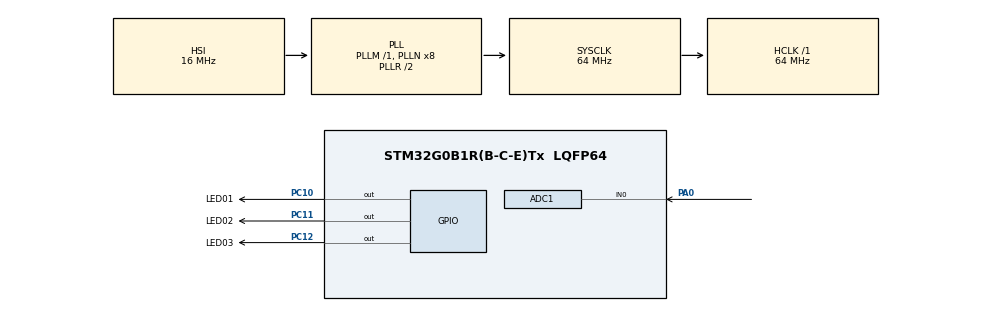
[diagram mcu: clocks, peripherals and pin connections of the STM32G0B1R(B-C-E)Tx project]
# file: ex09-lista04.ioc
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ADC1.Channel-1\#ChannelRegularConversion=ADC_CHANNEL_0
ADC1.NbrOfConversionFlag=1
ADC1.Rank-1\#ChannelRegularConversion=1
ADC1.SamplingTime-1\#ChannelRegularConversion=ADC_SAMPLINGTIME_COMMON_1
ADC1.SamplingTimeCommon1=ADC_SAMPLETIME_19CYCLES_5
ADC1.SelectedChannel=ADC_CHANNEL_0
ADC1.master=1
Mcu.Family=STM32G0
Mcu.Name=STM32G0B1R(B-C-E)Tx
Mcu.Package=LQFP64
PA0.Mode=IN0
PA0.Signal=ADC1_IN0
PA13.Mode=Serial_Wire
PA13.Signal=SYS_SWDIO
PA14-BOOT0.Mode=Serial_Wire
PA14-BOOT0.Signal=SYS_SWCLK
PC10.GPIO_Label=LED01
PC10.Signal=GPIO_Output
PC11.GPIO_Label=LED02
PC11.Signal=GPIO_Output
PC12.GPIO_Label=LED03
PC12.Signal=GPIO_Output
ProjectManager.HeapSize=0x200
ProjectManager.StackSize=0x400
ProjectManager.TargetToolchain=STM32CubeIDE
RCC.ADCFreq_Value=64000000
RCC.AHBFreq_Value=64000000
RCC.CortexFreq_Value=64000000
RCC.EXTERNAL_CLOCK_VALUE=48000
RCC.HCLKFreq_Value=64000000
RCC.HSE_VALUE=8000000
RCC.HSI48_VALUE=48000000
RCC.HSI_VALUE=16000000
RCC.LSE_VALUE=32768
RCC.SYSCLKFreq_VALUE=64000000
RCC.SYSCLKSource=RCC_SYSCLKSOURCE_PLLCLK
RCC.USBFreq_Value=48000000
RCC.VCOOutputFreq_Value=128000000
VP_SYS_VS_DBSignals.Mode=DisableDeadBatterySignals
board=custom

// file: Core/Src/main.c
/* USER CODE BEGIN Header */
/**
  ******************************************************************************
  * @file           : main.c
  * @brief          : Main program body
  ******************************************************************************
  * @attention
  *
  * Copyright (c) 2022 STMicroelectronics.
  * All rights reserved.
  *
  * This software is licensed under terms that can be found in the LICENSE file
  * in the root directory of this software component.
  * If no LICENSE file comes with this software, it is provided AS-IS.
  *
  ******************************************************************************
  */
/* USER CODE END Header */
#include "main.h"

/* USER CODE BEGIN Includes */
#include <stdint.h>
/* USER CODE END Includes */

ADC_HandleTypeDef hadc1;

void SystemClock_Config(void);
static void MX_GPIO_Init(void);
static void MX_ADC1_Init(void);

/* USER CODE BEGIN 0 */
uint16_t pot, r2, r1=270;
float volt;
/* USER CODE END 0 */

int main(void)
{

  /* MCU Configuration--------------------------------------------------------*/

  /* Reset of all peripherals, Initializes the Flash interface and the Systick. */
  HAL_Init();

  /* Configure the system clock */
  SystemClock_Config();

  /* Initialize all configured peripherals */
  MX_GPIO_Init();
  MX_ADC1_Init();
  /* USER CODE BEGIN 2 */
  HAL_ADCEx_Calibration_Start(&hadc1);
  /* USER CODE END 2 */

  /* Infinite loop */
  /* USER CODE BEGIN WHILE */
  while (1)
  {

	  //iniciando conversão
	  HAL_ADC_Start(&hadc1);

	  //tempo de espera para completar ciclo
	  HAL_ADC_PollForConversion(&hadc1, 1);

	  pot = HAL_ADC_GetValue(&hadc1);

	  //tempo de espera para completar ciclo
	  HAL_ADC_PollForConversion(&hadc1, 1);

	  volt = 3.3 / 4095.0 * pot;

	  r2=(volt/(3.3-volt))*r1;

    /* USER CODE END WHILE */

  }
}

void SystemClock_Config(void)
{
  RCC_OscInitTypeDef RCC_OscInitStruct = {0};
  RCC_ClkInitTypeDef RCC_ClkInitStruct = {0};

  /** Configure the main internal regulator output voltage
  */
  HAL_PWREx_ControlVoltageScaling(PWR_REGULATOR_VOLTAGE_SCALE1);
  /** Initializes the RCC Oscillators according to the specified parameters
  * in the RCC_OscInitTypeDef structure.
  */
  RCC_OscInitStruct.OscillatorType = RCC_OSCILLATORTYPE_HSI;
  RCC_OscInitStruct.HSIState = RCC_HSI_ON;
  RCC_OscInitStruct.HSIDiv = RCC_HSI_DIV1;
  RCC_OscInitStruct.HSICalibrationValue = RCC_HSICALIBRATION_DEFAULT;
  RCC_OscInitStruct.PLL.PLLState = RCC_PLL_ON;
  RCC_OscInitStruct.PLL.PLLSource = RCC_PLLSOURCE_HSI;
  RCC_OscInitStruct.PLL.PLLM = RCC_PLLM_DIV1;
  RCC_OscInitStruct.PLL.PLLN = 8;
  RCC_OscInitStruct.PLL.PLLP = RCC_PLLP_DIV2;
  RCC_OscInitStruct.PLL.PLLQ = RCC_PLLQ_DIV2;
  RCC_OscInitStruct.PLL.PLLR = RCC_PLLR_DIV2;
  if (HAL_RCC_OscConfig(&RCC_OscInitStruct) != HAL_OK)
  {
    Error_Handler();
  }
  /** Initializes the CPU, AHB and APB buses clocks
  */
  RCC_ClkInitStruct.ClockType = RCC_CLOCKTYPE_HCLK|RCC_CLOCKTYPE_SYSCLK
                              |RCC_CLOCKTYPE_PCLK1;
  RCC_ClkInitStruct.SYSCLKSource = RCC_SYSCLKSOURCE_PLLCLK;
  RCC_ClkInitStruct.AHBCLKDivider = RCC_SYSCLK_DIV1;
  RCC_ClkInitStruct.APB1CLKDivider = RCC_HCLK_DIV1;

  if (HAL_RCC_ClockConfig(&RCC_ClkInitStruct, FLASH_LATENCY_2) != HAL_OK)
  {
    Error_Handler();
  }
}

static void MX_ADC1_Init(void)
{

  ADC_ChannelConfTypeDef sConfig = {0};

  /** Configure the global features of the ADC (Clock, Resolution, Data Alignment and number of conversion)
  */
  hadc1.Instance = ADC1;
  hadc1.Init.ClockPrescaler = ADC_CLOCK_SYNC_PCLK_DIV2;
  hadc1.Init.Resolution = ADC_RESOLUTION_12B;
  hadc1.Init.DataAlign = ADC_DATAALIGN_RIGHT;
  hadc1.Init.ScanConvMode = ADC_SCAN_DISABLE;
  hadc1.Init.EOCSelection = ADC_EOC_SINGLE_CONV;
  hadc1.Init.LowPowerAutoWait = DISABLE;
  hadc1.Init.LowPowerAutoPowerOff = DISABLE;
  hadc1.Init.ContinuousConvMode = DISABLE;
  hadc1.Init.NbrOfConversion = 1;
  hadc1.Init.DiscontinuousConvMode = DISABLE;
  hadc1.Init.ExternalTrigConv = ADC_SOFTWARE_START;
  hadc1.Init.ExternalTrigConvEdge = ADC_EXTERNALTRIGCONVEDGE_NONE;
  hadc1.Init.DMAContinuousRequests = DISABLE;
  hadc1.Init.Overrun = ADC_OVR_DATA_PRESERVED;
  hadc1.Init.SamplingTimeCommon1 = ADC_SAMPLETIME_19CYCLES_5;
  hadc1.Init.SamplingTimeCommon2 = ADC_SAMPLETIME_1CYCLE_5;
  hadc1.Init.OversamplingMode = DISABLE;
  hadc1.Init.TriggerFrequencyMode = ADC_TRIGGER_FREQ_HIGH;
  if (HAL_ADC_Init(&hadc1) != HAL_OK)
  {
    Error_Handler();
  }
  /** Configure Regular Channel
  */
  sConfig.Channel = ADC_CHANNEL_0;
  sConfig.Rank = ADC_REGULAR_RANK_1;
  sConfig.SamplingTime = ADC_SAMPLINGTIME_COMMON_1;
  if (HAL_ADC_ConfigChannel(&hadc1, &sConfig) != HAL_OK)
  {
    Error_Handler();
  }

}

static void MX_GPIO_Init(void)
{
  GPIO_InitTypeDef GPIO_InitStruct = {0};

  /* GPIO Ports Clock Enable */
  __HAL_RCC_GPIOC_CLK_ENABLE();
  __HAL_RCC_GPIOA_CLK_ENABLE();

  /*Configure GPIO pin Output Level */
  HAL_GPIO_WritePin(GPIOC, LED02_Pin|LED03_Pin|LED01_Pin, GPIO_PIN_RESET);

  /*Configure GPIO pins : LED02_Pin LED03_Pin LED01_Pin */
  GPIO_InitStruct.Pin = LED02_Pin|LED03_Pin|LED01_Pin;
  GPIO_InitStruct.Mode = GPIO_MODE_OUTPUT_PP;
  GPIO_InitStruct.Pull = GPIO_NOPULL;
  GPIO_InitStruct.Speed = GPIO_SPEED_FREQ_LOW;
  HAL_GPIO_Init(GPIOC, &GPIO_InitStruct);

}

void Error_Handler(void)
{
  __disable_irq();
  while (1)
  {
  }
}
